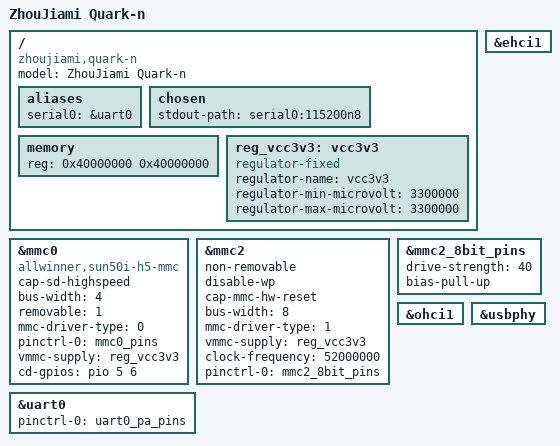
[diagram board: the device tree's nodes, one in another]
/*
 * Copyright (c) 2016 ARM Ltd.
 * Copyright (c) 2024 ZhouJiami <zjmitxwz@163.com>
 */
/dts-v1/;
#include "sun50i-h5.dtsi"

#include <dt-bindings/gpio/gpio.h>

/ {
	model = "ZhouJiami Quark-n";
	compatible = "zhoujiami,quark-n", "allwinner,sun50i-h5";

	aliases {
		serial0 = &uart0;
	};

	chosen {
		stdout-path = "serial0:115200n8";
	};

	memory {
		reg = <0x40000000 0x40000000>;
	};

	reg_vcc3v3: vcc3v3 {
		compatible = "regulator-fixed";
		regulator-name = "vcc3v3";
		regulator-min-microvolt = <3300000>;
		regulator-max-microvolt = <3300000>;
	};
};

&ehci1 {
	status = "okay";
};

&mmc0 {
	compatible = "allwinner,sun50i-h5-mmc",
		     "allwinner,sun50i-a64-mmc",
		     "allwinner,sun5i-a13-mmc";
	pinctrl-names = "default";
	cap-sd-highspeed;
	bus-width = <4>;
	removable = <1>;
	status = "okay";
	mmc-driver-type = <0>;
	pinctrl-0 = <&mmc0_pins>;
	vmmc-supply = <&reg_vcc3v3>;
	cd-gpios = <&pio 5 6 GPIO_ACTIVE_HIGH>;
};

&mmc2 {
	pinctrl-names = "default";
	non-removable;
	disable-wp;
	cap-mmc-hw-reset;
	status = "okay";
	bus-width = <8>;
	mmc-driver-type = <1>;
	vmmc-supply = <&reg_vcc3v3>;
	clock-frequency = <52000000>;
	pinctrl-0 = <&mmc2_8bit_pins>;
};

&mmc2_8bit_pins {
        /* Increase drive strength for DDR modes */
        drive-strength = <40>;
        /* eMMC is missing pull-ups */
        bias-pull-up;
};

&ohci1 {
	status = "okay";
};

&uart0 {
	pinctrl-names = "default";
	pinctrl-0 = <&uart0_pa_pins>;
	status = "okay";
};

&usbphy {
	status = "okay";
};
